# SPC1169 register map
File version: 2022071043481212
CPU: cm4 r1p0, little endian, no MPU, FPU, 4 interrupt priority bits
Registers are 32-bit, read-write, reset 0x0 unless marked. A register's access mark holds for its fields unless they carry their own. Offsets are from the block's base; [hi:lo] are bit positions; {n}, {i} and the like mark numbered series; 'fields as' and 'values as' point back to an identical list.

## DMAC
Base 0x40001C00
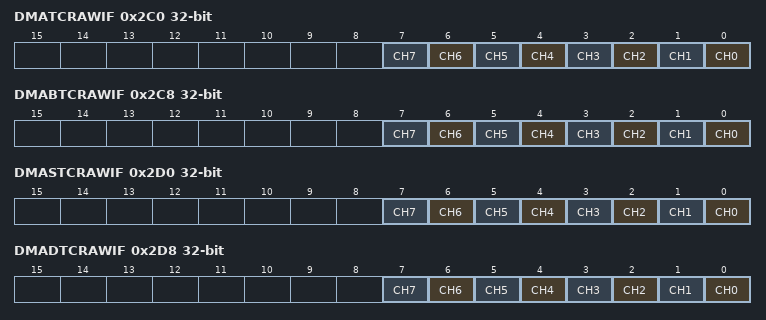
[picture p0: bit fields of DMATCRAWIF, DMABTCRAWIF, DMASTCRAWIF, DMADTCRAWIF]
0x2C0 DMATCRAWIF ro — DMA Transfer Complete Raw Interrupt Flag Register
  [all] fields
    0=NOT_OCCUR (Transfer not completed); 1=OCCUR (Transfer completed)
  [n] CH{n} (n=0..7) — Channel {n} transfer complete raw interrupt flag. This bit can be written for test purpose. It is not recommended to write for normal operation
0x2C8 DMABTCRAWIF ro — DMA Block Transfer Complete Raw Interrupt Flag Register
  fields as DMATCRAWIF
0x2D0 DMASTCRAWIF ro — DMA Source Transfer Complete Raw Interrupt Flag Register
  fields as DMATCRAWIF
0x2D8 DMADTCRAWIF ro — DMA Destination Transfer Complete Raw Interrupt Flag Register
  fields as DMATCRAWIF
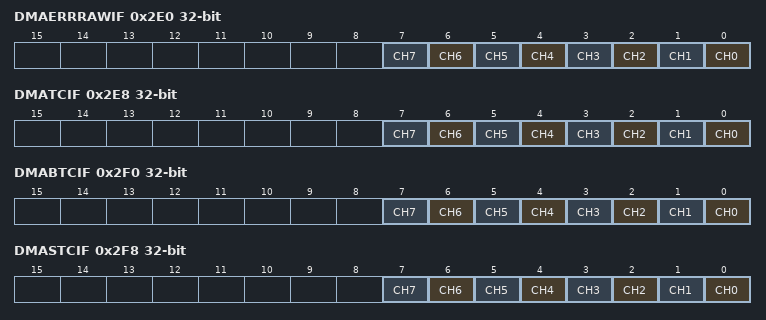
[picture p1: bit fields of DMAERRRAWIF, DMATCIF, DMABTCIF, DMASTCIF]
0x2E0 DMAERRRAWIF ro — DMA Error Raw Interrupt Flag Register
  [all] fields
    0=NOT_OCCUR (Error not occurred); 1=OCCUR (Error occurred)
  [n] CH{n} (n=0..7) — Channel {n} error raw interrupt flag. This bit can be written for test purpose. It is not recommended to write for normal operation
0x2E8 DMATCIF ro — DMA Transfer Complete Interrupt Flag Register
  [all] fields
    0=NOT_OCCUR (Transfer complete interrupt not occurred); 1=OCCUR (Transfer complete interrupt occurred)
  [n] CH{n} (n=0..7) — Channel {n} transfer complete interrupt flag
0x2F0 DMABTCIF ro — DMA Block Transfer Complete Interrupt Flag Register
  fields as DMATCIF
0x2F8 DMASTCIF ro — DMA Source Transfer Complete Interrupt Flag Register
  fields as DMATCIF
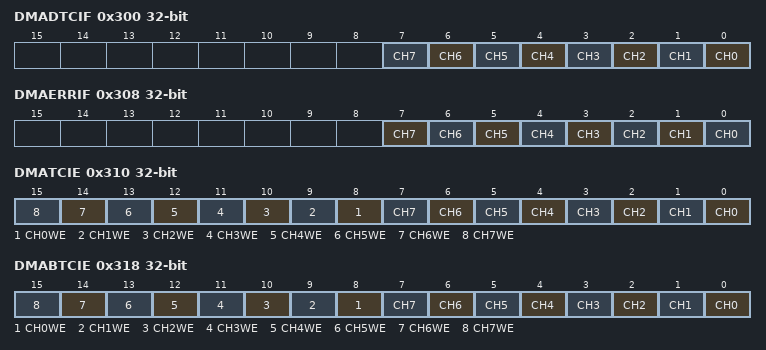
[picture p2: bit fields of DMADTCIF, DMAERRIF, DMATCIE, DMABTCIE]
0x300 DMADTCIF ro — DMA Destination Transfer Complete Interrupt Flag Register
  fields as DMATCIF
0x308 DMAERRIF ro — DMA Error Interrupt Flag Register
  [all] fields
    0=NOT_OCCUR (Error interrupt not occurred); 1=OCCUR (Error interrupt occurred)
  [7] CH7 — Channel 7 error interrupt flag
  [6] CH6 — Channel 6 error interrupt flag
  [5] CH5 — Channel 5 error interrupt flag
  [n] CH{n} (n=0..4) — Channel {n} error interrrupt flag
0x310 DMATCIE — DMA Transfer Complete Interrupt Enable Register
  [n+8] CH{n}WE (n=0..7) — CH{n} bit write enable
    0=DISABLE; 1=ENABLE (Enable. This bit is self-cleared to 0.)
  [n] CH{n} (n=0..7) — Channel {n} transfer complete interrupt enable
    0=DISABLE; 1=ENABLE
0x318 DMABTCIE — DMA Block Transfer Complete Interrupt Enable Register
  fields as DMATCIE
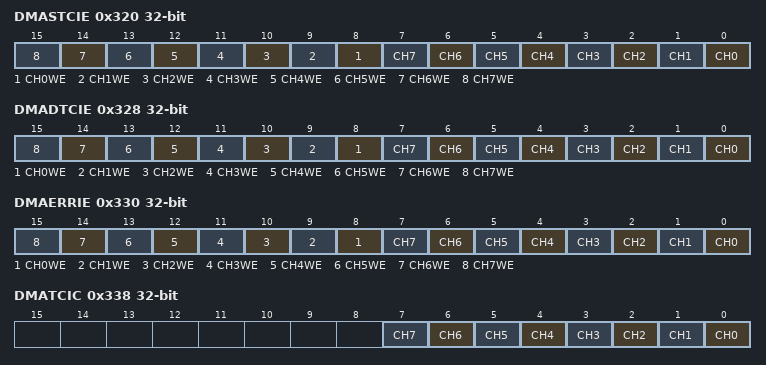
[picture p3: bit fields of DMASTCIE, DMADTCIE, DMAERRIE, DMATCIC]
0x320 DMASTCIE — DMA Source Transfer Complete Interrupt Enable Register
  fields as DMATCIE
0x328 DMADTCIE — DMA Destination Transfer Complete Interrupt Enable Register
  fields as DMATCIE
0x330 DMAERRIE — DMA Error Interrupt Enable Register
  [n+8] CH{n}WE (n=0..7) — CH{n} bit write enable
    0=DISABLE; 1=ENABLE (Enable. This bit is self-cleared to 0.)
  [n] CH{n} (n=0..7) — Channel {n} error interrupt enable
    0=DISABLE; 1=ENABLE
0x338 DMATCIC — DMA Transfer Complete Interrupt Clear Register
  [all] fields
    0=NO_EFFECT (Write a 0 has no effect and always reads back a 0.); 1=CLEAR (Write a 1 clears the interrupt raw flag and flag. This bit is self-cleared to 0.)
  [n] CH{n} (n=0..7) — Channel {n} transfer complete interrupt clear
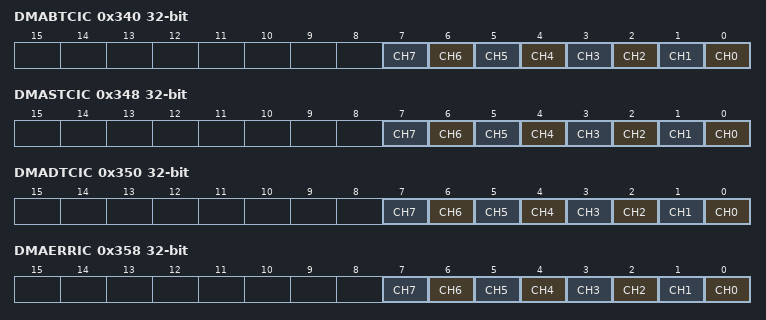
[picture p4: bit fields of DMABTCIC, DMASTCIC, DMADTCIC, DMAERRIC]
0x340 DMABTCIC — DMA Block Transfer Complete Interrupt Clear Register
  fields as DMATCIC
0x348 DMASTCIC — DMA Source Transfer Complete Interrupt Clear Register
  fields as DMATCIC
0x350 DMADTCIC — DMA Destination Transfer Complete Interrupt Clear Register
  fields as DMATCIC
0x358 DMAERRIC — DMA Error Interrupt Clear Register
  [all] fields
    values as the fields of DMATCIC
  [n] CH{n} (n=0..7) — Channel {n} error interrupt clear
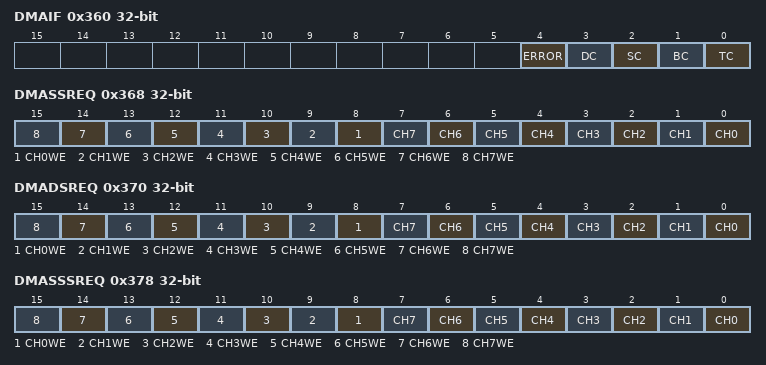
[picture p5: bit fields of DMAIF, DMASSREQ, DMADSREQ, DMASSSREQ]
0x360 DMAIF ro — DMA Combined Interrupt Flag Register
  [4] ERROR — Global error interrupt flag. This bit is the logic OR of DMAERRIF bits
    0=NOT_OCCUR (No error interrupt was generated); 1=OCCUR (Error interrupt was generated)
  [3] DC — Global destination transfer complete interrupt flag. This bit is the logic OR of DMATCIF bits
    0=NOT_OCCUR (No transfer complete interrupt was generated); 1=OCCUR (Transfer complete interrupt was generated)
  [2] SC — Global source transfer complete interrupt flag. This bit is the logic OR of DMATCIF bits
    values as DC
  [1] BC — Global block transfer complete interrupt flag. This bit is the logic OR of DMATCIF bits
    values as DC
  [0] TC — Global transfer complete interrupt flag. This bit is the logic OR of DMATCIF bits
    values as DC
0x368 DMASSREQ — DMA Source Software Transaction Request Register
  [n+8] CH{n}WE (n=0..7) — CH{n} bit write enable.
    0=DISABLE; 1=ENABLE (Enable. This bit is self-cleared to 0.)
  [n] CH{n} (n=0..7) — Channel {n} enable.
    0=DISABLE; 1=ENABLE
0x370 DMADSREQ — DMA Destination Software Transaction Request Register
  fields as DMASSREQ
0x378 DMASSSREQ — DMA Source Software Transaction Single Request Register
  [n+8] CH{n}WE (n=0..7) — CH{n} bit write enable.
    0=DISABLE; 1=ENABLE (Enable. This bit is self-cleared to 0.)
  [n] CH{n} (n=0..7) — Channel {n} enable.
    0=DISABLE (Source burst request); 1=ENABLE (Source single request)
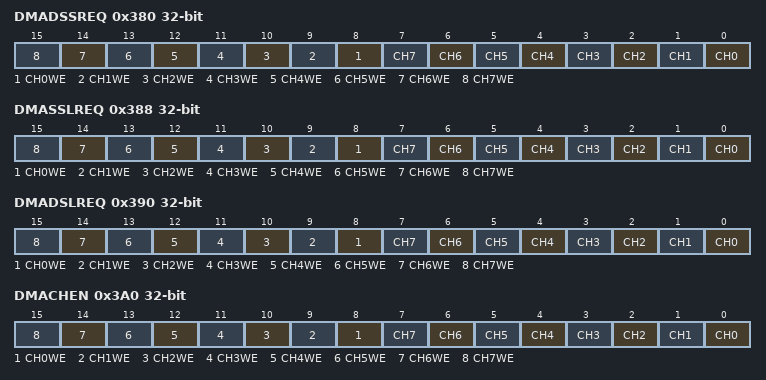
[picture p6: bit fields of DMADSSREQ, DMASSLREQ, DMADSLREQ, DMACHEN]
0x380 DMADSSREQ — DMA Destination Software Transaction Single Request Register
  [n+8] CH{n}WE (n=0..7) — CH{n} bit write enable.
    0=DISABLE; 1=ENABLE (Enable. This bit is self-cleared to 0.)
  [n] CH{n} (n=0..7) — Channel {n} enable.
    0=DISABLE (Destination burst request); 1=ENABLE (Destination single request)
0x388 DMASSLREQ — DMA Source Software Transaction Last Request Register
  [n+8] CH{n}WE (n=0..7) — CH{n} bit write enable.
    0=DISABLE; 1=ENABLE (Enable. This bit is self-cleared to 0.)
  [n] CH{n} (n=0..7) — Channel {n} enable.
    0=DISABLE (Not last transaction in current block); 1=ENABLE (Last transaction in current block)
0x390 DMADSLREQ — DMA Destination Software Transaction Last Request Register
  fields as DMASSLREQ
0x398 DMAEN — DMA Enable Register
  [0] EN — DMA enable, If the global channel enable bit is cleared while any channel is still active, then DMAEN.EN still returns 1 to indicate that there are channels still active until hardware has terminated all activity on all channels, at which point the DMAEN.EN bit returns 0.
    0=DISABLE; 1=ENABLE
0x3A0 DMACHEN — DMA Channel Enable Register
  [n+8] CH{n}WE (n=0..7) — CH{n} bit write enable
    0=DISABLE; 1=ENABLE (Enable. This bit is self-cleared to 0.)
  [n] CH{n} (n=0..7) — Channel {n} enable, automatically cleared if DMA transfer finished.
    0=DISABLE; 1=ENABLE
